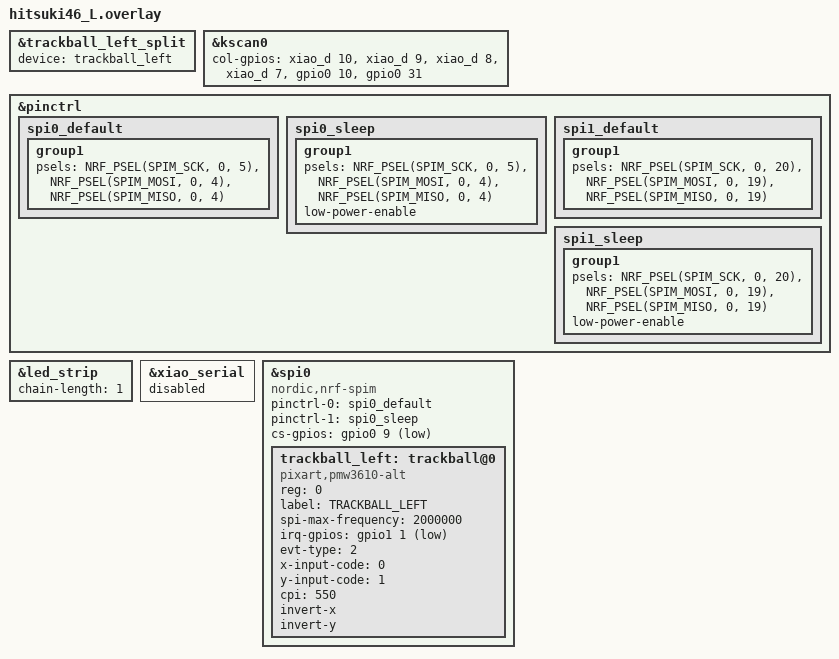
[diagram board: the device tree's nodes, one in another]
#include "hitsuki46.dtsi"
#include <dt-bindings/zmk/input_transform.h>
#include <input/processors.dtsi>

// Configure trackball_left_split to forward data from trackball_left to central
&trackball_left_split {
    device = <&trackball_left>;
};

&kscan0 {
        col-gpios
            = <&xiao_d 10 GPIO_ACTIVE_HIGH>
            , <&xiao_d 9 GPIO_ACTIVE_HIGH>
            , <&xiao_d 8 GPIO_ACTIVE_HIGH>
            , <&xiao_d 7 GPIO_ACTIVE_HIGH>
            , <&gpio0 10 GPIO_ACTIVE_HIGH>
            , <&gpio0 31 GPIO_ACTIVE_HIGH>
            ;
};

// Pin control for SPI0 (Trackball) and SPI1 (WS2812 LED)
&pinctrl {
    spi0_default: spi0_default {
        group1 {
            psels = <NRF_PSEL(SPIM_SCK, 0, 5)>,
                <NRF_PSEL(SPIM_MOSI, 0, 4)>,
                <NRF_PSEL(SPIM_MISO, 0, 4)>;
        };
    };

    spi0_sleep: spi0_sleep {
        group1 {
            psels = <NRF_PSEL(SPIM_SCK, 0, 5)>,
                <NRF_PSEL(SPIM_MOSI, 0, 4)>,
                <NRF_PSEL(SPIM_MISO, 0, 4)>;
            low-power-enable;
        };
    };

    spi1_default: spi1_default {
        group1 {
            psels = <NRF_PSEL(SPIM_SCK, 0, 20)>,
                <NRF_PSEL(SPIM_MOSI, 0, 19)>,
                <NRF_PSEL(SPIM_MISO, 0, 19)>;
        };
    };

    spi1_sleep: spi1_sleep {
        group1 {
            psels = <NRF_PSEL(SPIM_SCK, 0, 20)>,
                <NRF_PSEL(SPIM_MOSI, 0, 19)>,
                <NRF_PSEL(SPIM_MISO, 0, 19)>;
            low-power-enable;
        };
    };
};

// Override led_strip to set blue color
&led_strip {
    status = "okay";
    chain-length = <1>;
    // Pre-set WS2812 to blue color (0x0000FF)
};

&xiao_serial { status = "disabled"; };

&spi0 {
    status = "okay";
    compatible = "nordic,nrf-spim";
    pinctrl-0 = <&spi0_default>;
    pinctrl-1 = <&spi0_sleep>;
    pinctrl-names = "default", "sleep";
    cs-gpios = <&gpio0 9 GPIO_ACTIVE_LOW>;

    trackball_left: trackball@0 {
        status = "okay";
        compatible = "pixart,pmw3610-alt";
        reg = <0>;
        label = "TRACKBALL_LEFT";
        spi-max-frequency = <2000000>;
        irq-gpios = <&gpio1 1 (GPIO_ACTIVE_LOW | GPIO_PULL_UP)>;
        evt-type = <2>;  // INPUT_EV_REL - relative movement events
        x-input-code = <0>;  // INPUT_REL_X
        y-input-code = <1>;  // INPUT_REL_Y

        // CPI setting (200-3200, step 200, default 600)
        cpi = <550>;

        // 180 degree orientation (invert both X and Y)
        invert-x;
        invert-y;

        // Power management
        // NOTE: force-awake was removed to fix cursor drift issue when idle
        // The sensor will now use normal downshift mode (RUN -> REST1 -> REST2 -> REST3)
    };
};


// split_inputs is enabled to forward trackball data to central
